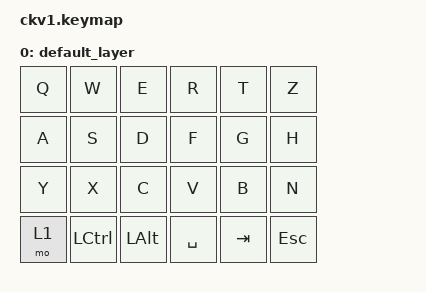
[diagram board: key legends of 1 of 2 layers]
#include <behaviors.dtsi>
#include <dt-bindings/zmk/keys.h>

/ {
  behaviors {
    hp_pwr: hold_pwr {
      compatible = "zmk,behavior-hold-tap";
      label = "HOLD_PWR";
      #binding-cells = <2>;
      tapping-term-ms = <1000>;
      quick-tap-ms = <0>;
      bindings = <&kp>, <&ext_power EP_TOG>;
    };

    hp_rst: hold_rst {
      compatible = "zmk,behavior-hold-tap";
      label = "HOLD_RST";
      #binding-cells = <2>;
      tapping-term-ms = <1000>;
      quick-tap-ms = <0>;
      bindings = <&kp>, <&bootloader>;
    };
  };

  keymap {
    compatible = "zmk,keymap";
    default_layer {
      bindings = <
        // QWERTZ Base Layer
        &kp Q    &kp W    &kp E    &kp R    &kp T    &kp Z
        &kp A    &kp S    &kp D    &kp F    &kp G    &kp H
        &kp Y    &kp X    &kp C    &kp V    &kp B    &kp N
        &mo 1    &kp LCTL &kp LALT &kp SPACE &kp TAB  &kp ESC
      >;
    };

    layer_1 {
      bindings = <
        // Outer (P0.11)          Pinky (P1.00)
        &hp_pwr NUM_1  EP_TOG    &hp_rst NUM_2  BOOTLOADER
        &kp NUM_3      &kp NUM_4 &kp NUM_5      &kp NUM_6
        &kp NUM_7      &kp NUM_8 &kp NUM_9      &kp NUM_0
        &trans         &trans    &trans         &trans
      >;
    };
  };
};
